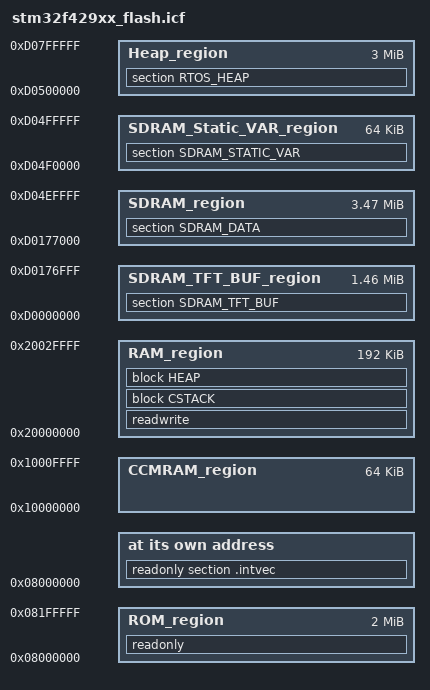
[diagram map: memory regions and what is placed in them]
/*###ICF### Section handled by ICF editor, don't touch! ****/
/*-Editor annotation file-*/
/* IcfEditorFile="$TOOLKIT_DIR$\config\ide\IcfEditor\cortex_v1_0.xml" */
/*-Specials-*/
define symbol __ICFEDIT_intvec_start__ = 0x08000000;
/*-Memory Regions-*/
define symbol __ICFEDIT_region_ROM_start__ = 0x08000000;
define symbol __ICFEDIT_region_ROM_end__   = 0x081FFFFF;

define symbol __ICFEDIT_region_RAM_start__ = 0x20000000;
define symbol __ICFEDIT_region_RAM_end__   = 0x2002FFFF;

define symbol __ICFEDIT_region_CCMRAM_start__ = 0x10000000;
define symbol __ICFEDIT_region_CCMRAM_end__   = 0x1000FFFF;

define symbol __ICFEDIT_region_TFT_BUF_START__   = 0xd0000000;
define symbol __ICFEDIT_region_TFT_BUF_FINISH__  = 0xd0176fff;

define symbol __ICFEDIT_region_SDRAM_start__ = 0xd0177000;
define symbol __ICFEDIT_region_SDRAM_end__   = 0xd04EFFFF;

define symbol __ICFEDIT_region_SDRAM_Static_VAR_start__ = 0xd04f0000;
define symbol __ICFEDIT_region_SDRAM_Static_VAR_end__   = 0xd04fffff;

define symbol __ICFEDIT_region_HeapMem_start__ = 0xd0500000;
define symbol __ICFEDIT_region_HeapMem_end__   = 0xd07fffff;

/*-Sizes-*/
define symbol __ICFEDIT_size_cstack__ = 0x400;
define symbol __ICFEDIT_size_heap__   = 0x150;
/**** End of ICF editor section. ###ICF###*/


define memory mem with size = 4G;
define region ROM_region                 = mem:[from __ICFEDIT_region_ROM_start__               to   __ICFEDIT_region_ROM_end__];
define region RAM_region                 = mem:[from __ICFEDIT_region_RAM_start__               to   __ICFEDIT_region_RAM_end__];
define region CCMRAM_region              = mem:[from __ICFEDIT_region_CCMRAM_start__            to   __ICFEDIT_region_CCMRAM_end__];
define region SDRAM_region               = mem:[from __ICFEDIT_region_SDRAM_start__             to   __ICFEDIT_region_SDRAM_end__  ];
define region SDRAM_TFT_BUF_region       = mem:[from __ICFEDIT_region_TFT_BUF_START__           to   __ICFEDIT_region_TFT_BUF_FINISH__  ];
define region SDRAM_Static_VAR_region    = mem:[from __ICFEDIT_region_SDRAM_Static_VAR_start__  to   __ICFEDIT_region_SDRAM_Static_VAR_end__    ];
define region Heap_region                = mem:[from __ICFEDIT_region_HeapMem_start__           to   __ICFEDIT_region_HeapMem_end__]; 

define block CSTACK    with alignment = 8, size = __ICFEDIT_size_cstack__   { };
define block HEAP      with alignment = 8, size = __ICFEDIT_size_heap__     { };

initialize by copy { readwrite };
do not initialize  { section .noinit };

place at address mem:__ICFEDIT_intvec_start__ { readonly section .intvec };

place in ROM_region   { readonly };
place in RAM_region   { readwrite,
                        block CSTACK, block HEAP };
"RAMHeap": place in Heap_region   { section RTOS_HEAP };
place in SDRAM_TFT_BUF_region   { section SDRAM_TFT_BUF };
place in SDRAM_region           { section SDRAM_DATA };
place in SDRAM_Static_VAR_region    { section SDRAM_STATIC_VAR };

